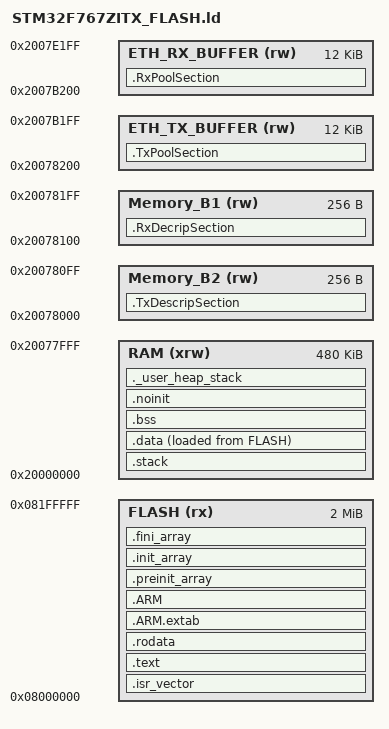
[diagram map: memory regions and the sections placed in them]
/*
******************************************************************************
**
** @file        : LinkerScript.ld
**
** @author      : Auto-generated by STM32CubeIDE
**
**  Abstract    : Linker script for NUCLEO-F767ZI Board embedding STM32F767ZITx Device from stm32f7 series
**                      2048KBytes FLASH
**                      512KBytes RAM
**
**                Set heap size, stack size and stack location according
**                to application requirements.
**
**                Set memory bank area and size if external memory is used
**
**  Target      : STMicroelectronics STM32
**
**  Distribution: The file is distributed as is, without any warranty
**                of any kind.
**
******************************************************************************
** @attention
**
** Copyright (c) 2025 STMicroelectronics.
** All rights reserved.
**
** This software is licensed under terms that can be found in the LICENSE file
** in the root directory of this software component.
** If no LICENSE file comes with this software, it is provided AS-IS.
**
******************************************************************************
*/

/* Entry Point */
ENTRY(Reset_Handler)

/* The MSP stack is the first thing in RAM (.stack below), in DTCM, top at
   _estack, growing DOWN. Its lowest 1 KB is an MPU no-access guard
   (core/mpu.cpp): an overflow faults at once (MemManage, recorded by
   core/fault.cpp) instead of running into data. 9 KB = 8 KB usable + guard.
   Measured peak: ~2.4 KB with TLS/MQTT running. */
_Min_Stack_Size = 0x2400; /* reserved MSP stack incl. the 1 KB guard */
_Min_Heap_Size = 0x0;     /* required amount of heap (newlib malloc, barely used) */

/* Memories definition */
MEMORY
{
  /* 480 KB: the top 32 KB (0x20078000..) is the Ethernet DMA area below,
     kept out of RAM so .bss can never grow into it unnoticed */
  RAM      (xrw)     : ORIGIN = 0x20000000,   LENGTH = 480K
  FLASH    (rx)      : ORIGIN = 0x08000000,   LENGTH = 2048K
  ETH_RX_BUFFER (rw) : ORIGIN = 0x2007B200,   LENGTH = 0x3000
  ETH_TX_BUFFER (rw) : ORIGIN = 0x20078200,   LENGTH = 0x3000
  Memory_B1(rw)      : ORIGIN = 0x20078100,  LENGTH = 0x100
  Memory_B2(rw)      : ORIGIN = 0x20078000,  LENGTH = 0x100
}

/* Sections */
SECTIONS
{

  /* The startup code into "FLASH" Rom type memory */
  .isr_vector :
  {
    . = ALIGN(4);
    KEEP(*(.isr_vector)) /* Startup code */
    . = ALIGN(4);
  } >FLASH

  /* The program code and other data into "FLASH" Rom type memory */
  .text :
  {
    . = ALIGN(4);
    *(.text)           /* .text sections (code) */
    *(.text*)          /* .text* sections (code) */
    *(.glue_7)         /* glue arm to thumb code */
    *(.glue_7t)        /* glue thumb to arm code */
    *(.eh_frame)

    KEEP (*(.init))
    KEEP (*(.fini))

    . = ALIGN(4);
    _etext = .;        /* define a global symbols at end of code */
  } >FLASH

  /* Constant data into "FLASH" Rom type memory */
  .rodata :
  {
    . = ALIGN(4);
    *(.rodata)         /* .rodata sections (constants, strings, etc.) */
    *(.rodata*)        /* .rodata* sections (constants, strings, etc.) */
    . = ALIGN(4);
  } >FLASH

  .ARM.extab (READONLY) : /* The "READONLY" keyword is only supported in GCC11 and later, remove it if using GCC10 or earlier. */
  {
    . = ALIGN(4);
    *(.ARM.extab* .gnu.linkonce.armextab.*)
    . = ALIGN(4);
  } >FLASH

  .ARM (READONLY) : /* The "READONLY" keyword is only supported in GCC11 and later, remove it if using GCC10 or earlier. */
  {
    . = ALIGN(4);
    __exidx_start = .;
    *(.ARM.exidx*)
    __exidx_end = .;
    . = ALIGN(4);
  } >FLASH

  .preinit_array (READONLY) : /* The "READONLY" keyword is only supported in GCC11 and later, remove it if using GCC10 or earlier. */
  {
    . = ALIGN(4);
    PROVIDE_HIDDEN (__preinit_array_start = .);
    KEEP (*(.preinit_array*))
    PROVIDE_HIDDEN (__preinit_array_end = .);
    . = ALIGN(4);
  } >FLASH

  .init_array (READONLY) : /* The "READONLY" keyword is only supported in GCC11 and later, remove it if using GCC10 or earlier. */
  {
    . = ALIGN(4);
    PROVIDE_HIDDEN (__init_array_start = .);
    KEEP (*(SORT(.init_array.*)))
    KEEP (*(.init_array*))
    PROVIDE_HIDDEN (__init_array_end = .);
    . = ALIGN(4);
  } >FLASH

  .fini_array (READONLY) : /* The "READONLY" keyword is only supported in GCC11 and later, remove it if using GCC10 or earlier. */
  {
    . = ALIGN(4);
    PROVIDE_HIDDEN (__fini_array_start = .);
    KEEP (*(SORT(.fini_array.*)))
    KEEP (*(.fini_array*))
    PROVIDE_HIDDEN (__fini_array_end = .);
    . = ALIGN(4);
  } >FLASH

  /* Used by the startup to initialize data */
  _sidata = LOADADDR(.data);

  /* MSP stack at the start of RAM, see _Min_Stack_Size */
  .stack (NOLOAD) :
  {
    . = ALIGN(8);
    _sstack = .;
    . = . + _Min_Stack_Size;
    . = ALIGN(8);
    _estack = .;
  } >RAM

  /* Initialized data sections into "RAM" Ram type memory */
  .data :
  {
    . = ALIGN(4);
    _sdata = .;        /* create a global symbol at data start */
    *(.data)           /* .data sections */
    *(.data*)          /* .data* sections */
    *(.RamFunc)        /* .RamFunc sections */
    *(.RamFunc*)       /* .RamFunc* sections */

    . = ALIGN(4);
    _edata = .;        /* define a global symbol at data end */

  } >RAM AT> FLASH

  /* Uninitialized data section into "RAM" Ram type memory */
  . = ALIGN(4);
  .bss :
  {
    /* This is used by the startup in order to initialize the .bss section */
    _sbss = .;         /* define a global symbol at bss start */
    __bss_start__ = _sbss;
    *(.bss)
    *(.bss*)
    *(COMMON)

    . = ALIGN(4);
    _ebss = .;         /* define a global symbol at bss end */
    __bss_end__ = _ebss;
  } >RAM

  /* Not zeroed by the startup code: survives software / watchdog resets.
     Random after power-on, so contents must carry their own validity check */
  .noinit (NOLOAD) :
  {
    . = ALIGN(4);
    *(.noinit)
    *(.noinit*)
    . = ALIGN(4);
  } >RAM

  /* Heap from here up to _heap_limit (end of RAM, below the DMA area);
     this section only checks that _Min_Heap_Size fits */
  ._user_heap_stack :
  {
    . = ALIGN(8);
    PROVIDE ( end = . );
    PROVIDE ( _end = . );
    . = . + _Min_Heap_Size;
    . = ALIGN(8);
  } >RAM
  _heap_limit = ORIGIN(RAM) + LENGTH(RAM);
  .RxDecripSection   (NOLOAD) : { *(.RxDecripSection) } >Memory_B1
  .TxDescripSection  (NOLOAD) : { *(.TxDecripSection) } >Memory_B2
  .RxPoolSection     (NOLOAD) : { *(.RxPoolSection)   } >ETH_RX_BUFFER
  .TxPoolSection     (NOLOAD) : { *(.RxPoolSection)   } >ETH_TX_BUFFER
  /* Remove information from the compiler libraries */
  /DISCARD/ :
  {
    libc.a ( * )
    libm.a ( * )
    libgcc.a ( * )
  }

  .ARM.attributes 0 : { *(.ARM.attributes) }
}
